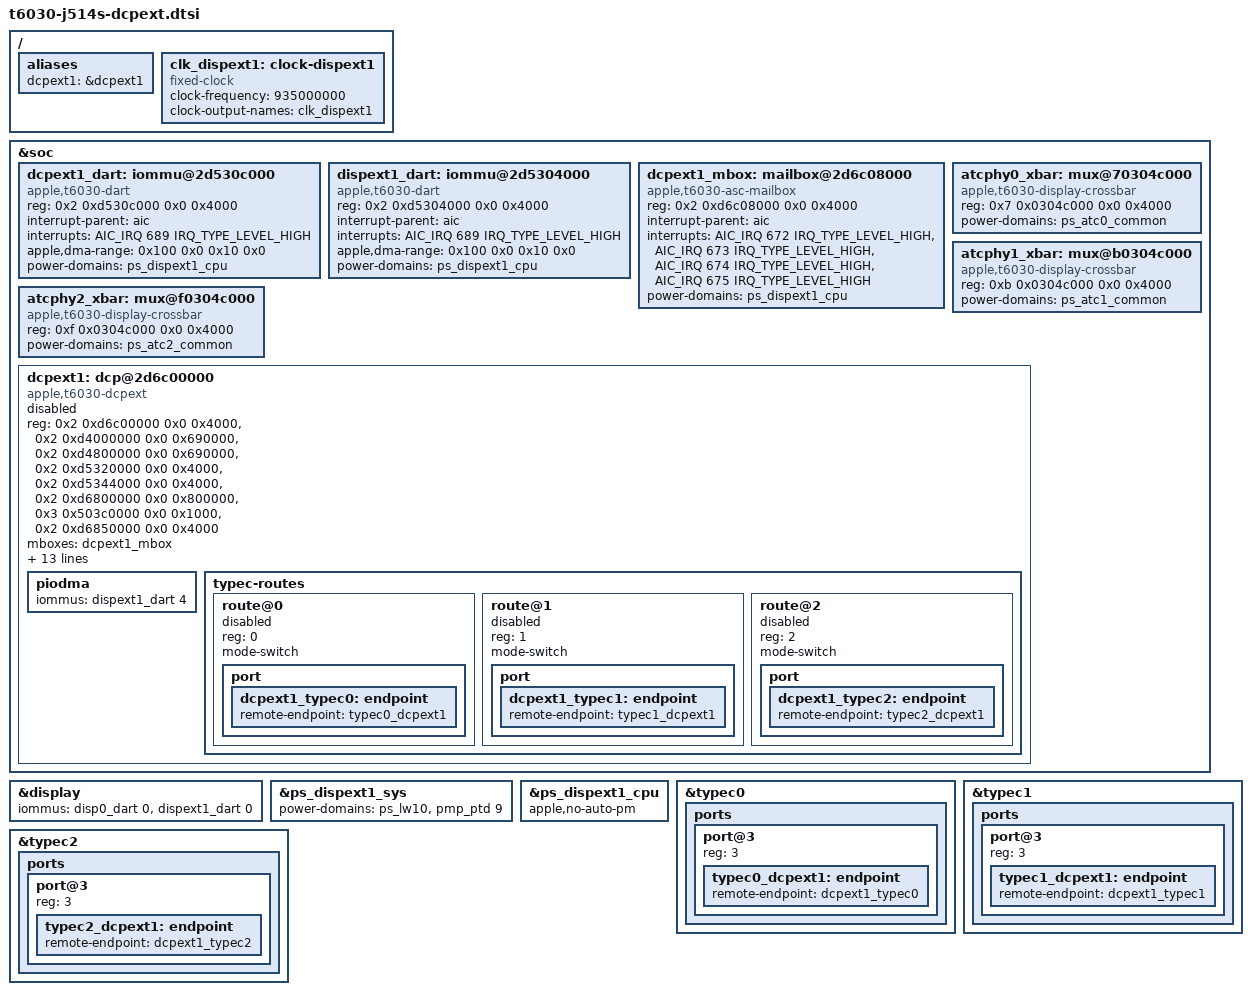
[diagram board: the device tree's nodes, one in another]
// SPDX-License-Identifier: GPL-2.0+ OR MIT
/*
 * Apple MacBook Pro (14-inch, M3 Pro) J514S: external display controller
 * DCPEXT1 and the USB-C DisplayPort routes.
 *
 * DCPEXT1 drives the three USB-C ports through the DisplayPort alternate
 * mode. The Type-C port controller enters the mode and reports pin
 * assignment and HPD to the mode switches linked to its connector: the
 * port's ATC PHY (lanes, orientation) and one route of DCPEXT1 (port@3 of
 * the connector). Each route names the port's DP PHY, its display crossbar
 * (ATC core + 0x4c000), DCPEXT1's crossbar source selector (2) and the
 * DPTX target index of the port's ATC (CONNECT target 0x8000 | ATC << 4).
 *
 * The controller's firmware (the panel's DCP firmware 14.7.0 image) must be
 * reserved by the boot loader before Linux may start it: the loader
 * publishes apple,firmware-version, -compat and -uuid and the memory-region
 * of the firmware segments, then enables dcpext1 and its routes together.
 * A route available without its controller would hold the connector's
 * port controller in deferred probe.
 *
 * The DISPEXT1 power chain hangs from the PMP device-state request of
 * DISPEXT1, so the PMP acknowledges the controller before any of its
 * domains is powered; the DARTs and the mailbox, which power the chain on
 * probe, are enabled here, as are the crossbars, each powered through its
 * ATC's common domain while a controller is connected to it.
 *
 * Copyright The Asahi Linux Contributors
 */

/ {
	aliases {
		dcpext1 = &dcpext1;
	};

	/* DISPEXT1 clock ID 356 (ADT dispext1 clock-ids, frequency index 100). */
	clk_dispext1: clock-dispext1 {
		compatible = "fixed-clock";
		#clock-cells = <0>;
		clock-frequency = <935000000>;
		clock-output-names = "clk_dispext1";
	};
};

&soc {
	/* DCPEXT1 coprocessor DART: SID5. */
	dcpext1_dart: iommu@2d530c000 {
		compatible = "apple,t6030-dart", "apple,t8110-dart";
		reg = <0x2 0xd530c000 0x0 0x4000>;
		interrupt-parent = <&aic>;
		interrupts = <AIC_IRQ 689 IRQ_TYPE_LEVEL_HIGH>;
		#iommu-cells = <1>;
		apple,dma-range = <0x100 0x0 0x10 0x0>;
		power-domains = <&ps_dispext1_cpu>;
	};

	/* DISPEXT1 display frontend DART: SID0 scanout, SID4 PIODMA. */
	dispext1_dart: iommu@2d5304000 {
		compatible = "apple,t6030-dart", "apple,t8110-dart";
		reg = <0x2 0xd5304000 0x0 0x4000>;
		interrupt-parent = <&aic>;
		interrupts = <AIC_IRQ 689 IRQ_TYPE_LEVEL_HIGH>;
		#iommu-cells = <1>;
		apple,dma-range = <0x100 0x0 0x10 0x0>;
		power-domains = <&ps_dispext1_cpu>;
	};

	dcpext1_mbox: mailbox@2d6c08000 {
		compatible = "apple,t6030-asc-mailbox", "apple,asc-mailbox-v4";
		reg = <0x2 0xd6c08000 0x0 0x4000>;
		interrupt-parent = <&aic>;
		interrupts = <AIC_IRQ 672 IRQ_TYPE_LEVEL_HIGH>,
			     <AIC_IRQ 673 IRQ_TYPE_LEVEL_HIGH>,
			     <AIC_IRQ 674 IRQ_TYPE_LEVEL_HIGH>,
			     <AIC_IRQ 675 IRQ_TYPE_LEVEL_HIGH>;
		interrupt-names = "send-empty", "send-not-empty",
				  "recv-empty", "recv-not-empty";
		power-domains = <&ps_dispext1_cpu>;
		#mbox-cells = <0>;
	};

	/* Display crossbars of the three USB-C ATCs (core + 0x4c000). */
	atcphy0_xbar: mux@70304c000 {
		compatible = "apple,t6030-display-crossbar";
		reg = <0x7 0x0304c000 0x0 0x4000>;
		#mux-control-cells = <1>;
		power-domains = <&ps_atc0_common>;
	};

	atcphy1_xbar: mux@b0304c000 {
		compatible = "apple,t6030-display-crossbar";
		reg = <0xb 0x0304c000 0x0 0x4000>;
		#mux-control-cells = <1>;
		power-domains = <&ps_atc1_common>;
	};

	atcphy2_xbar: mux@f0304c000 {
		compatible = "apple,t6030-display-crossbar";
		reg = <0xf 0x0304c000 0x0 0x4000>;
		#mux-control-cells = <1>;
		power-domains = <&ps_atc2_common>;
	};

	dcpext1: dcp@2d6c00000 {
		compatible = "apple,t6030-dcpext";
		/*
		 * ADT dcpext1 reg[0] (first 16K) and reg[1], with dispext1's six
		 * display ranges as disp-0..5 in their ADT order; disp-5 is the
		 * PMP device-state aperture all display controllers share.
		 */
		reg = <0x2 0xd6c00000 0x0 0x4000>,
		      <0x2 0xd4000000 0x0 0x690000>,
		      <0x2 0xd4800000 0x0 0x690000>,
		      <0x2 0xd5320000 0x0 0x4000>,
		      <0x2 0xd5344000 0x0 0x4000>,
		      <0x2 0xd6800000 0x0 0x800000>,
		      <0x3 0x503c0000 0x0 0x1000>,
		      <0x2 0xd6850000 0x0 0x4000>;
		reg-names = "coproc", "disp-0", "disp-1", "disp-2", "disp-3",
			    "disp-4", "disp-5", "iop-vbar";
		mboxes = <&dcpext1_mbox>;
		mbox-names = "mbox";
		iommus = <&dcpext1_dart 5>;
		power-domains = <&ps_dispext1_cpu>;
		clocks = <&clk_dispext1>;
		apple,dcp-index = <2>;
		apple,connector-type = "USB-C";
		phys = <&atcphy0 PHY_TYPE_DP>, <&atcphy1 PHY_TYPE_DP>,
		       <&atcphy2 PHY_TYPE_DP>;
		phy-names = "typec0", "typec1", "typec2";
		mux-controls = <&atcphy0_xbar 0>, <&atcphy1_xbar 0>,
			       <&atcphy2_xbar 0>;
		mux-control-names = "typec0", "typec1", "typec2";
		/* DCPEXT1's crossbar source selector on every port. */
		apple,typec-mux-indices = <2 2 2>;
		/* DPTX target index: the port's ATC. */
		apple,typec-dptx-phys = <0 1 2>;
		status = "disabled";	/* Enabled by the loader with its firmware. */

		piodma {
			iommus = <&dispext1_dart 4>;
		};

		typec-routes {
			#address-cells = <1>;
			#size-cells = <0>;

			route@0 {
				reg = <0>;
				mode-switch;
				status = "disabled";

				port {
					dcpext1_typec0: endpoint {
						remote-endpoint = <&typec0_dcpext1>;
					};
				};
			};

			route@1 {
				reg = <1>;
				mode-switch;
				status = "disabled";

				port {
					dcpext1_typec1: endpoint {
						remote-endpoint = <&typec1_dcpext1>;
					};
				};
			};

			route@2 {
				reg = <2>;
				mode-switch;
				status = "disabled";

				port {
					dcpext1_typec2: endpoint {
						remote-endpoint = <&typec2_dcpext1>;
					};
				};
			};
		};
	};
};

/*
 * The display subsystem's buffers are scanned out by every display
 * controller: DCPEXT1 fetches through its frontend DART's stream 0.
 */
&display {
	iommus = <&disp0_dart 0>, <&dispext1_dart 0>;
};

/* The PMP acknowledges DISPEXT1 before its chain is powered. */
&ps_dispext1_sys {
	power-domains = <&ps_lw10>, <&pmp_ptd 9>;
};

/*
 * Linux starts the DCPEXT1 coprocessor cold: its CPU domain must stay at the
 * requested state, without automatic gating.
 */
&ps_dispext1_cpu {
	apple,no-auto-pm;
};

/* Left back (SPMI 1-0c), ATC0. */
&typec0 {
	ports {
		port@3 {
			reg = <3>;

			typec0_dcpext1: endpoint {
				remote-endpoint = <&dcpext1_typec0>;
			};
		};
	};
};

/* Left front (SPMI 1-0a), ATC1. */
&typec1 {
	ports {
		port@3 {
			reg = <3>;

			typec1_dcpext1: endpoint {
				remote-endpoint = <&dcpext1_typec1>;
			};
		};
	};
};

/* Right (SPMI 2-08), ATC2. */
&typec2 {
	ports {
		port@3 {
			reg = <3>;

			typec2_dcpext1: endpoint {
				remote-endpoint = <&dcpext1_typec2>;
			};
		};
	};
};
